# STM32L052C6T6 register map
File version: 1.0
Registers are 32-bit, access not given, reset 0x0 unless marked. A register's access mark holds for its fields unless they carry their own. Offsets are from the block's base; [hi:lo] are bit positions; {n}, {i} and the like mark numbered series.

## USBFS
Base 0x40005C00
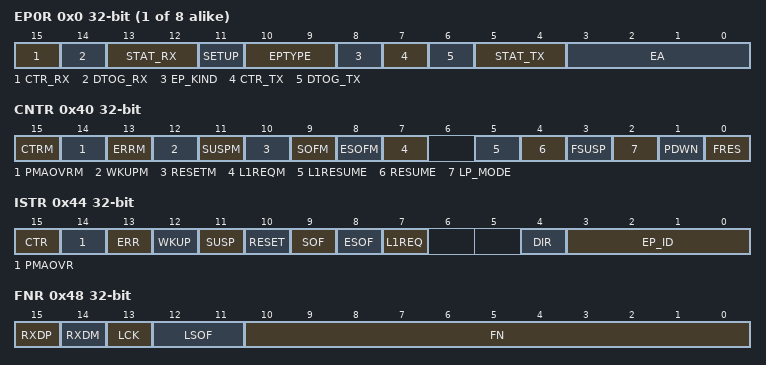
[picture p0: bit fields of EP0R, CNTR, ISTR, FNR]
{0x0+4i} EP{i}R (i=0..7)
  [15] CTR_RX, [14] DTOG_RX, [13:12] STAT_RX, [11] SETUP, [10:9] EPTYPE, [8] EP_KIND, [7] CTR_TX, [6] DTOG_TX, [5:4] STAT_TX, [3:0] EA
0x40 CNTR
  [15] CTRM, [14] PMAOVRM, [13] ERRM, [12] WKUPM, [11] SUSPM, [10] RESETM, [9] SOFM, [8] ESOFM, [7] L1REQM, [5] L1RESUME, [4] RESUME, [3] FSUSP, [2] LP_MODE, [1] PDWN, [0] FRES
0x44 ISTR
  [15] CTR, [14] PMAOVR, [13] ERR, [12] WKUP, [11] SUSP, [10] RESET, [9] SOF, [8] ESOF, [7] L1REQ, [4] DIR, [3:0] EP_ID
0x48 FNR
  [15] RXDP, [14] RXDM, [13] LCK, [12:11] LSOF, [10:0] FN
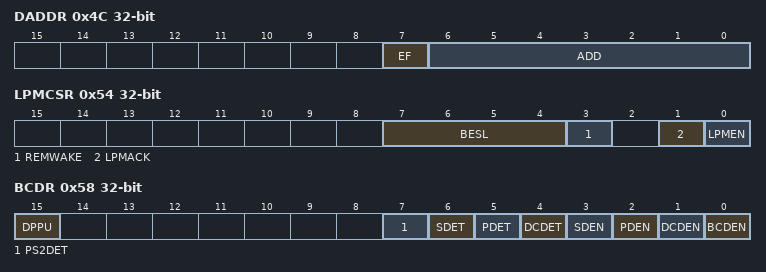
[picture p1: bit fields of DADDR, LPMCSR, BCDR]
0x4C DADDR
  [7] EF, [6:0] ADD
0x50 BTABLE
  [15:3] BTABLE
0x54 LPMCSR
  [7:4] BESL, [3] REMWAKE, [1] LPMACK, [0] LPMEN
0x58 BCDR
  [15] DPPU, [7] PS2DET, [6] SDET, [5] PDET, [4] DCDET, [3] SDEN, [2] PDEN, [1] DCDEN, [0] BCDEN

## CRS
Base 0x40006C00
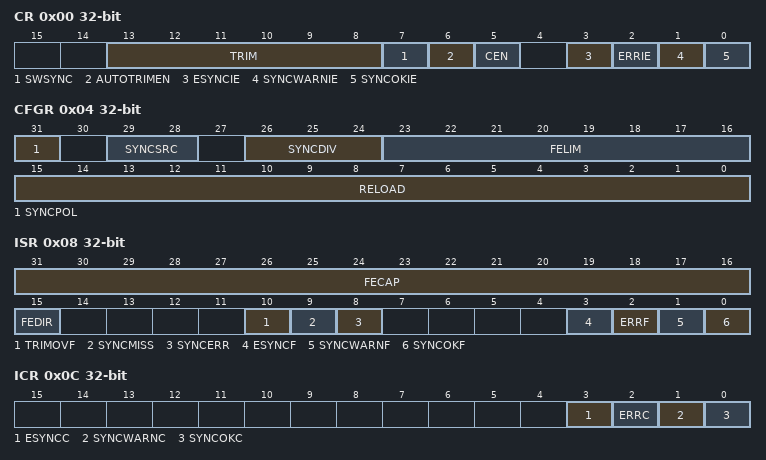
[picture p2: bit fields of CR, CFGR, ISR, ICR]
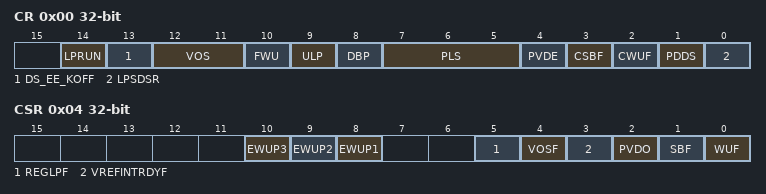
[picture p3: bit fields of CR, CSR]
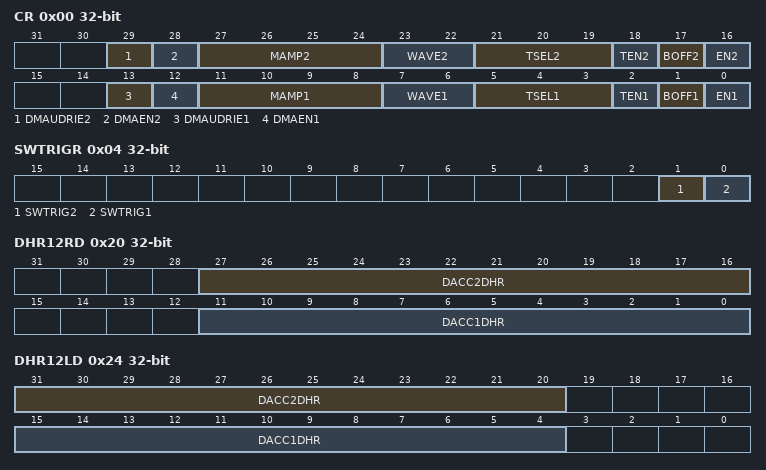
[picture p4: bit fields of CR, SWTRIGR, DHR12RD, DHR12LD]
0x00 CR
  [13:8] TRIM, [7] SWSYNC, [6] AUTOTRIMEN, [5] CEN, [3] ESYNCIE, [2] ERRIE, [1] SYNCWARNIE, [0] SYNCOKIE
0x04 CFGR
  [31] SYNCPOL, [29:28] SYNCSRC, [26:24] SYNCDIV, [23:16] FELIM, [15:0] RELOAD
0x08 ISR
  [31:16] FECAP, [15] FEDIR, [10] TRIMOVF, [9] SYNCMISS, [8] SYNCERR, [3] ESYNCF, [2] ERRF, [1] SYNCWARNF, [0] SYNCOKF
0x0C ICR
  [3] ESYNCC, [2] ERRC, [1] SYNCWARNC, [0] SYNCOKC

## PWR
Base 0x40007000
0x00 CR
  [14] LPRUN, [13] DS_EE_KOFF, [12:11] VOS, [10] FWU, [9] ULP, [8] DBP, [7:5] PLS, [4] PVDE, [3] CSBF, [2] CWUF, [1] PDDS, [0] LPSDSR
0x04 CSR
  [10] EWUP3, [9] EWUP2, [8] EWUP1, [5] REGLPF, [4] VOSF, [3] VREFINTRDYF, [2] PVDO, [1] SBF, [0] WUF

## DAC12
Base 0x40007400
0x00 CR
  [29] DMAUDRIE2, [28] DMAEN2, [27:24] MAMP2, [23:22] WAVE2, [21:19] TSEL2, [18] TEN2, [17] BOFF2, [16] EN2, [13] DMAUDRIE1, [12] DMAEN1, [11:8] MAMP1, [7:6] WAVE1, [5:3] TSEL1, [2] TEN1, [1] BOFF1, [0] EN1
0x04 SWTRIGR
  [1] SWTRIG2, [0] SWTRIG1
0x08 DHR12R1
  [11:0] DACC1DHR
0x0C DHR12L1
  [15:4] DACC1DHR
0x10 DHR8R1
  [7:0] DACC1DHR
0x14 DHR12R2
  [11:0] DACC2DHR
0x18 DHR12L2
  [15:4] DACC2DHR
0x1C DHR8R2
  [7:0] DACC2DHR
0x20 DHR12RD
  [27:16] DACC2DHR, [11:0] DACC1DHR
0x24 DHR12LD
  [31:20] DACC2DHR, [15:4] DACC1DHR
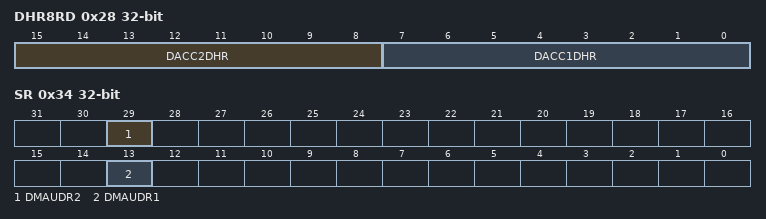
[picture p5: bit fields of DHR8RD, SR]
0x28 DHR8RD
  [15:8] DACC2DHR, [7:0] DACC1DHR
0x2C DOR1
  [11:0] DACC1DOR
0x30 DOR2
  [11:0] DACC2DOR
0x34 SR
  [29] DMAUDR2, [13] DMAUDR1

## LPTIM1
Base 0x40007C00
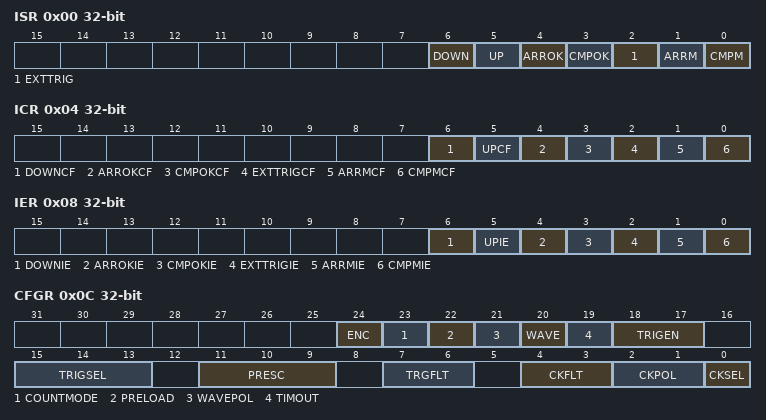
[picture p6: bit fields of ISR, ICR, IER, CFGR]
0x00 ISR
  [6] DOWN, [5] UP, [4] ARROK, [3] CMPOK, [2] EXTTRIG, [1] ARRM, [0] CMPM
0x04 ICR
  [6] DOWNCF, [5] UPCF, [4] ARROKCF, [3] CMPOKCF, [2] EXTTRIGCF, [1] ARRMCF, [0] CMPMCF
0x08 IER
  [6] DOWNIE, [5] UPIE, [4] ARROKIE, [3] CMPOKIE, [2] EXTTRIGIE, [1] ARRMIE, [0] CMPMIE
0x0C CFGR
  [24] ENC, [23] COUNTMODE, [22] PRELOAD, [21] WAVEPOL, [20] WAVE, [19] TIMOUT, [18:17] TRIGEN, [15:13] TRIGSEL, [11:9] PRESC, [7:6] TRGFLT, [4:3] CKFLT, [2:1] CKPOL, [0] CKSEL
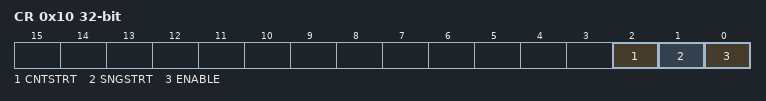
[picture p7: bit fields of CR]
0x10 CR
  [2] CNTSTRT, [1] SNGSTRT, [0] ENABLE
0x14 CMP
  [15:0] CMP
0x18 ARR
  [15:0] ARR
0x1C CNT
  [15:0] CNT

## COMP
Base 0x40010000
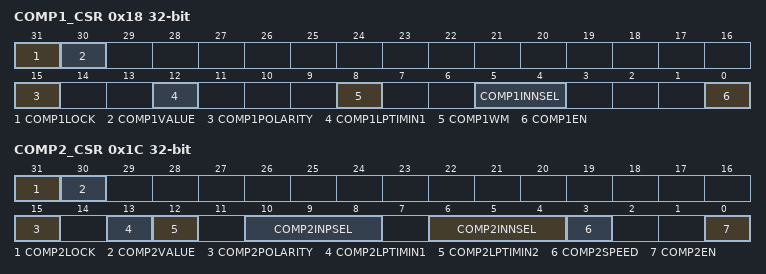
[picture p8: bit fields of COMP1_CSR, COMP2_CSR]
0x18 COMP1_CSR
  [31] COMP1LOCK, [30] COMP1VALUE, [15] COMP1POLARITY, [12] COMP1LPTIMIN1, [8] COMP1WM, [5:4] COMP1INNSEL, [0] COMP1EN
0x1C COMP2_CSR
  [31] COMP2LOCK, [30] COMP2VALUE, [15] COMP2POLARITY, [13] COMP2LPTIMIN1, [12] COMP2LPTIMIN2, [10:8] COMP2INPSEL, [6:4] COMP2INNSEL, [3] COMP2SPEED, [0] COMP2EN

## SYSCFG
Base 0x40010000
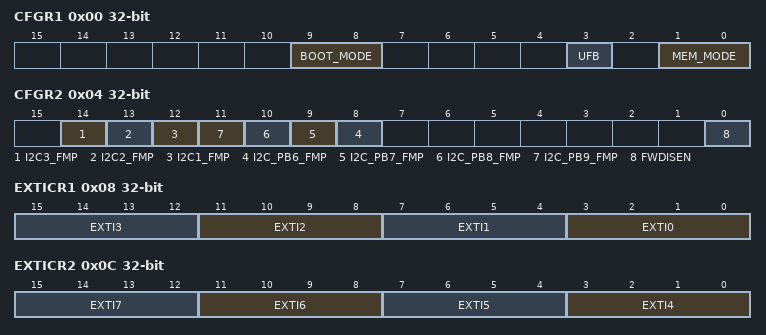
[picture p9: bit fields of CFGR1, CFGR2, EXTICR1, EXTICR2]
0x00 CFGR1
  [9:8] BOOT_MODE, [3] UFB, [1:0] MEM_MODE
0x04 CFGR2
  [14] I2C3_FMP, [13] I2C2_FMP, [12] I2C1_FMP, [n+2] I2C_PB{n}_FMP (n=6..9), [0] FWDISEN
0x08 EXTICR1
  [4n+3:4n] EXTI{n} (n=0..3)
0x0C EXTICR2
  [4n-13:4n-16] EXTI{n} (n=4..7)
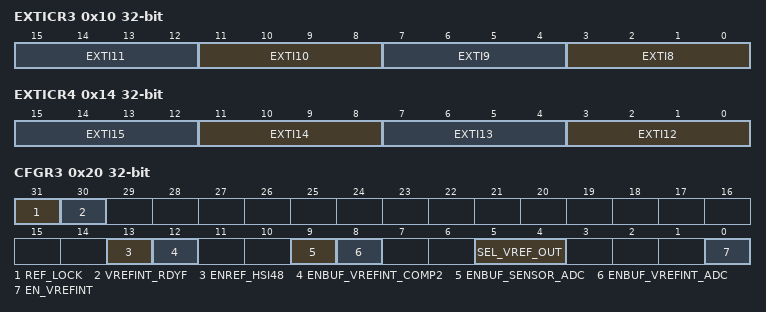
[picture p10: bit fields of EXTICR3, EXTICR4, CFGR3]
0x10 EXTICR3
  [4n-29:4n-32] EXTI{n} (n=8..11)
0x14 EXTICR4
  [4n-45:4n-48] EXTI{n} (n=12..15)
0x20 CFGR3
  [31] REF_LOCK, [30] VREFINT_RDYF, [13] ENREF_HSI48, [12] ENBUF_VREFINT_COMP2, [9] ENBUF_SENSOR_ADC, [8] ENBUF_VREFINT_ADC, [5:4] SEL_VREF_OUT, [0] EN_VREFINT
